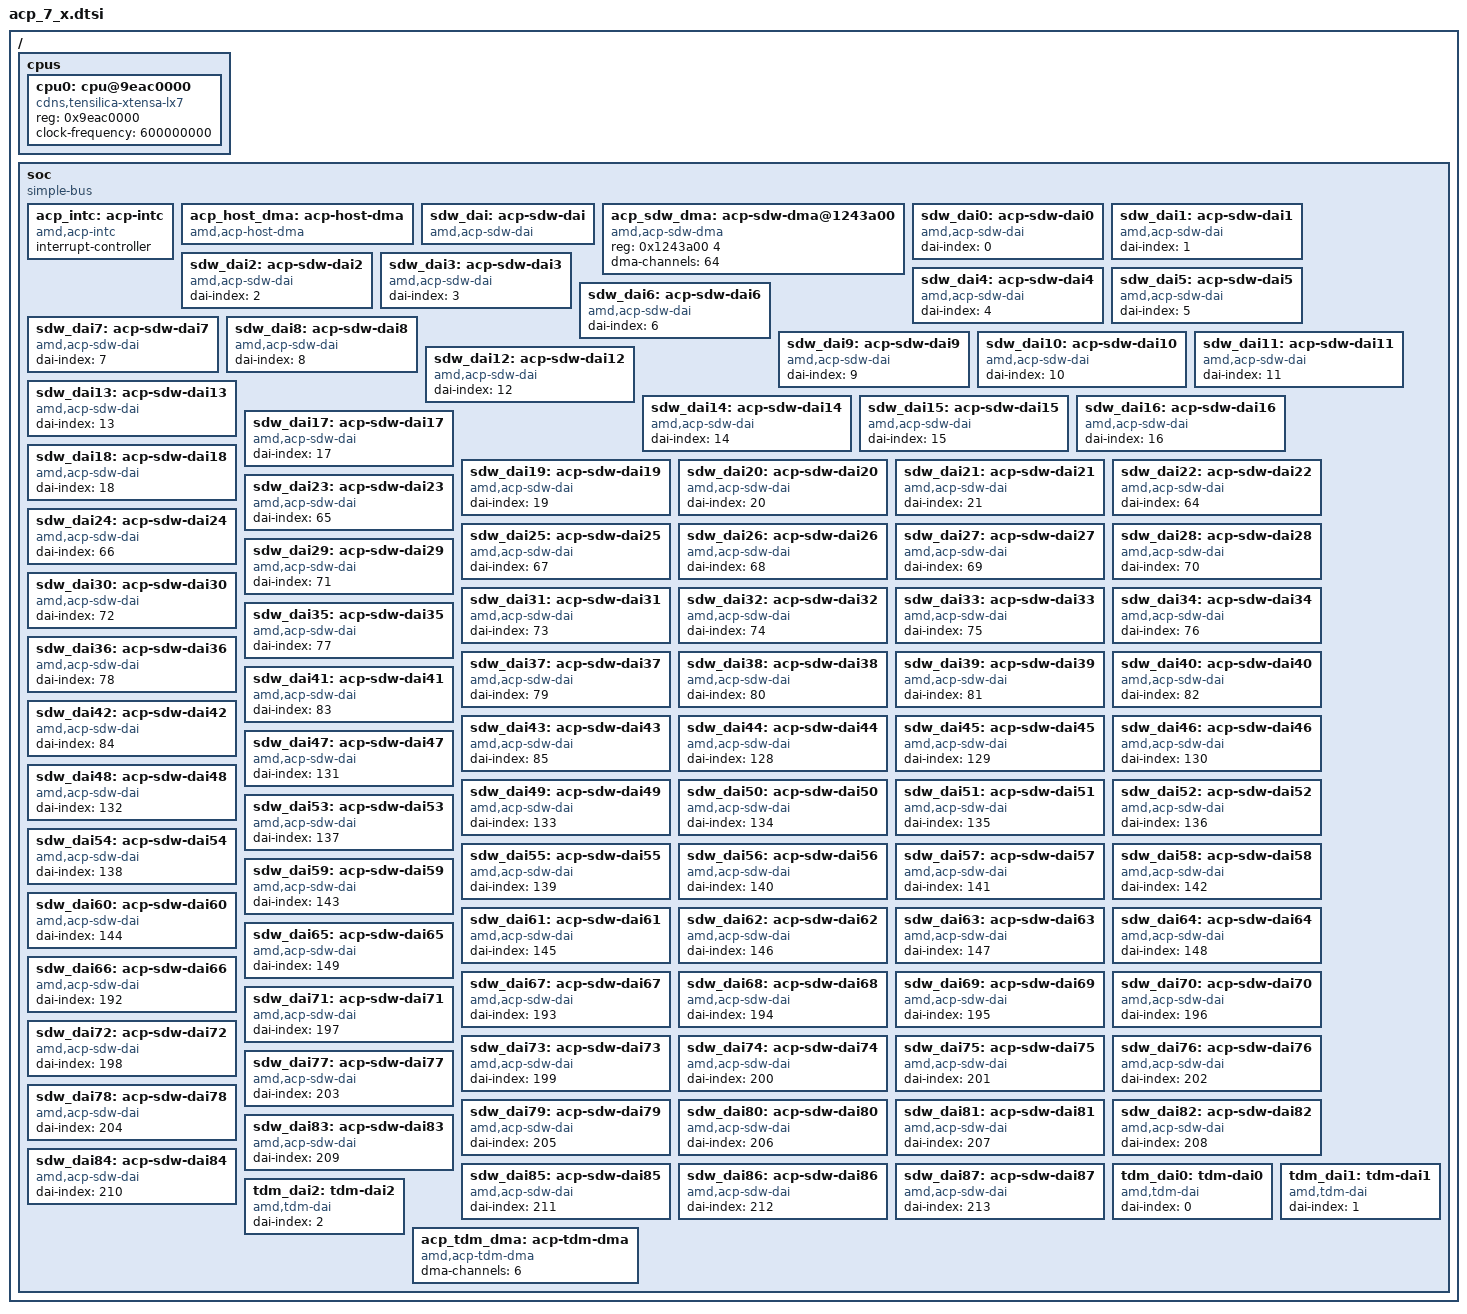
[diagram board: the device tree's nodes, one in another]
/*
 * SPDX-FileCopyrightText: Copyright (c) 2026 AMD
 *
 * SPDX-License-Identifier: Apache-2.0
 */

#include <xtensa/xtensa.dtsi>

/ {
	cpus {
		#address-cells = <1>;
		#size-cells = <0>;

		cpu0: cpu@9eac0000 {
			compatible = "cdns,tensilica-xtensa-lx7";
			reg = <0x9eac0000>;
			device_type = "cpu";
			clock-frequency = <600000000>;
		};
	};

	soc {
		compatible = "simple-bus";
		ranges;
		#address-cells = <1>;
		#size-cells = <1>;

		acp_intc: acp-intc {
			compatible = "amd,acp-intc";
			interrupt-controller;
			#interrupt-cells = <1>;
			status = "okay";
		};

		acp_host_dma: acp-host-dma {
			compatible = "amd,acp-host-dma";
			#dma-cells = <3>;
			status = "okay";
		};

		sdw_dai: acp-sdw-dai {
			compatible = "amd,acp-sdw-dai";
			status = "okay";
		};

		acp_sdw_dma: acp-sdw-dma@1243a00 {
			compatible = "amd,acp-sdw-dma";
			reg = <0x1243a00 4>;
			dma-channels = <64>;
			#dma-cells = <3>;
			status = "okay";
		};

		sdw_dai0: acp-sdw-dai0 {
			compatible = "amd,acp-sdw-dai";
			dai-index = <0>;
			status = "okay";
		};

		sdw_dai1: acp-sdw-dai1 {
			compatible = "amd,acp-sdw-dai";
			dai-index = <1>;
			status = "okay";
		};

		sdw_dai2: acp-sdw-dai2 {
			compatible = "amd,acp-sdw-dai";
			dai-index = <2>;
			status = "okay";
		};

		sdw_dai3: acp-sdw-dai3 {
			compatible = "amd,acp-sdw-dai";
			dai-index = <3>;
			status = "okay";
		};

		sdw_dai4: acp-sdw-dai4 {
			compatible = "amd,acp-sdw-dai";
			dai-index = <4>;
			status = "okay";
		};

		sdw_dai5: acp-sdw-dai5 {
			compatible = "amd,acp-sdw-dai";
			dai-index = <5>;
			status = "okay";
		};

		sdw_dai6: acp-sdw-dai6 {
			compatible = "amd,acp-sdw-dai";
			dai-index = <6>;
			status = "okay";
		};

		sdw_dai7: acp-sdw-dai7 {
			compatible = "amd,acp-sdw-dai";
			dai-index = <7>;
			status = "okay";
		};

		sdw_dai8: acp-sdw-dai8 {
			compatible = "amd,acp-sdw-dai";
			dai-index = <8>;
			status = "okay";
		};

		sdw_dai9: acp-sdw-dai9 {
			compatible = "amd,acp-sdw-dai";
			dai-index = <9>;
			status = "okay";
		};

		sdw_dai10: acp-sdw-dai10 {
			compatible = "amd,acp-sdw-dai";
			dai-index = <10>;
			status = "okay";
		};

		sdw_dai11: acp-sdw-dai11 {
			compatible = "amd,acp-sdw-dai";
			dai-index = <11>;
			status = "okay";
		};

		sdw_dai12: acp-sdw-dai12 {
			compatible = "amd,acp-sdw-dai";
			dai-index = <12>;
			status = "okay";
		};

		sdw_dai13: acp-sdw-dai13 {
			compatible = "amd,acp-sdw-dai";
			dai-index = <13>;
			status = "okay";
		};

		sdw_dai14: acp-sdw-dai14 {
			compatible = "amd,acp-sdw-dai";
			dai-index = <14>;
			status = "okay";
		};

		sdw_dai15: acp-sdw-dai15 {
			compatible = "amd,acp-sdw-dai";
			dai-index = <15>;
			status = "okay";
		};

		sdw_dai16: acp-sdw-dai16 {
			compatible = "amd,acp-sdw-dai";
			dai-index = <16>;
			status = "okay";
		};

		sdw_dai17: acp-sdw-dai17 {
			compatible = "amd,acp-sdw-dai";
			dai-index = <17>;
			status = "okay";
		};

		sdw_dai18: acp-sdw-dai18 {
			compatible = "amd,acp-sdw-dai";
			dai-index = <18>;
			status = "okay";
		};

		sdw_dai19: acp-sdw-dai19 {
			compatible = "amd,acp-sdw-dai";
			dai-index = <19>;
			status = "okay";
		};

		sdw_dai20: acp-sdw-dai20 {
			compatible = "amd,acp-sdw-dai";
			dai-index = <20>;
			status = "okay";
		};

		sdw_dai21: acp-sdw-dai21 {
			compatible = "amd,acp-sdw-dai";
			dai-index = <21>;
			status = "okay";
		};

		sdw_dai22: acp-sdw-dai22 {
			compatible = "amd,acp-sdw-dai";
			dai-index = <64>;
			status = "okay";
		};

		sdw_dai23: acp-sdw-dai23 {
			compatible = "amd,acp-sdw-dai";
			dai-index = <65>;
			status = "okay";
		};

		sdw_dai24: acp-sdw-dai24 {
			compatible = "amd,acp-sdw-dai";
			dai-index = <66>;
			status = "okay";
		};

		sdw_dai25: acp-sdw-dai25 {
			compatible = "amd,acp-sdw-dai";
			dai-index = <67>;
			status = "okay";
		};

		sdw_dai26: acp-sdw-dai26 {
			compatible = "amd,acp-sdw-dai";
			dai-index = <68>;
			status = "okay";
		};

		sdw_dai27: acp-sdw-dai27 {
			compatible = "amd,acp-sdw-dai";
			dai-index = <69>;
			status = "okay";
		};

		sdw_dai28: acp-sdw-dai28 {
			compatible = "amd,acp-sdw-dai";
			dai-index = <70>;
			status = "okay";
		};

		sdw_dai29: acp-sdw-dai29 {
			compatible = "amd,acp-sdw-dai";
			dai-index = <71>;
			status = "okay";
		};

		sdw_dai30: acp-sdw-dai30 {
			compatible = "amd,acp-sdw-dai";
			dai-index = <72>;
			status = "okay";
		};

		sdw_dai31: acp-sdw-dai31 {
			compatible = "amd,acp-sdw-dai";
			dai-index = <73>;
			status = "okay";
		};

		sdw_dai32: acp-sdw-dai32 {
			compatible = "amd,acp-sdw-dai";
			dai-index = <74>;
			status = "okay";
		};

		sdw_dai33: acp-sdw-dai33 {
			compatible = "amd,acp-sdw-dai";
			dai-index = <75>;
			status = "okay";
		};

		sdw_dai34: acp-sdw-dai34 {
			compatible = "amd,acp-sdw-dai";
			dai-index = <76>;
			status = "okay";
		};

		sdw_dai35: acp-sdw-dai35 {
			compatible = "amd,acp-sdw-dai";
			dai-index = <77>;
			status = "okay";
		};

		sdw_dai36: acp-sdw-dai36 {
			compatible = "amd,acp-sdw-dai";
			dai-index = <78>;
			status = "okay";
		};

		sdw_dai37: acp-sdw-dai37 {
			compatible = "amd,acp-sdw-dai";
			dai-index = <79>;
			status = "okay";
		};

		sdw_dai38: acp-sdw-dai38 {
			compatible = "amd,acp-sdw-dai";
			dai-index = <80>;
			status = "okay";
		};

		sdw_dai39: acp-sdw-dai39 {
			compatible = "amd,acp-sdw-dai";
			dai-index = <81>;
			status = "okay";
		};

		sdw_dai40: acp-sdw-dai40 {
			compatible = "amd,acp-sdw-dai";
			dai-index = <82>;
			status = "okay";
		};

		sdw_dai41: acp-sdw-dai41 {
			compatible = "amd,acp-sdw-dai";
			dai-index = <83>;
			status = "okay";
		};

		sdw_dai42: acp-sdw-dai42 {
			compatible = "amd,acp-sdw-dai";
			dai-index = <84>;
			status = "okay";
		};

		sdw_dai43: acp-sdw-dai43 {
			compatible = "amd,acp-sdw-dai";
			dai-index = <85>;
			status = "okay";
		};

		sdw_dai44: acp-sdw-dai44 {
			compatible = "amd,acp-sdw-dai";
			dai-index = <128>;
			status = "okay";
		};

		sdw_dai45: acp-sdw-dai45 {
			compatible = "amd,acp-sdw-dai";
			dai-index = <129>;
			status = "okay";
		};

		sdw_dai46: acp-sdw-dai46 {
			compatible = "amd,acp-sdw-dai";
			dai-index = <130>;
			status = "okay";
		};

		sdw_dai47: acp-sdw-dai47 {
			compatible = "amd,acp-sdw-dai";
			dai-index = <131>;
			status = "okay";
		};

		sdw_dai48: acp-sdw-dai48 {
			compatible = "amd,acp-sdw-dai";
			dai-index = <132>;
			status = "okay";
		};

		sdw_dai49: acp-sdw-dai49 {
			compatible = "amd,acp-sdw-dai";
			dai-index = <133>;
			status = "okay";
		};

		sdw_dai50: acp-sdw-dai50 {
			compatible = "amd,acp-sdw-dai";
			dai-index = <134>;
			status = "okay";
		};

		sdw_dai51: acp-sdw-dai51 {
			compatible = "amd,acp-sdw-dai";
			dai-index = <135>;
			status = "okay";
		};

		sdw_dai52: acp-sdw-dai52 {
			compatible = "amd,acp-sdw-dai";
			dai-index = <136>;
			status = "okay";
		};

		sdw_dai53: acp-sdw-dai53 {
			compatible = "amd,acp-sdw-dai";
			dai-index = <137>;
			status = "okay";
		};

		sdw_dai54: acp-sdw-dai54 {
			compatible = "amd,acp-sdw-dai";
			dai-index = <138>;
			status = "okay";
		};

		sdw_dai55: acp-sdw-dai55 {
			compatible = "amd,acp-sdw-dai";
			dai-index = <139>;
			status = "okay";
		};

		sdw_dai56: acp-sdw-dai56 {
			compatible = "amd,acp-sdw-dai";
			dai-index = <140>;
			status = "okay";
		};

		sdw_dai57: acp-sdw-dai57 {
			compatible = "amd,acp-sdw-dai";
			dai-index = <141>;
			status = "okay";
		};

		sdw_dai58: acp-sdw-dai58 {
			compatible = "amd,acp-sdw-dai";
			dai-index = <142>;
			status = "okay";
		};

		sdw_dai59: acp-sdw-dai59 {
			compatible = "amd,acp-sdw-dai";
			dai-index = <143>;
			status = "okay";
		};

		sdw_dai60: acp-sdw-dai60 {
			compatible = "amd,acp-sdw-dai";
			dai-index = <144>;
			status = "okay";
		};

		sdw_dai61: acp-sdw-dai61 {
			compatible = "amd,acp-sdw-dai";
			dai-index = <145>;
			status = "okay";
		};

		sdw_dai62: acp-sdw-dai62 {
			compatible = "amd,acp-sdw-dai";
			dai-index = <146>;
			status = "okay";
		};

		sdw_dai63: acp-sdw-dai63 {
			compatible = "amd,acp-sdw-dai";
			dai-index = <147>;
			status = "okay";
		};

		sdw_dai64: acp-sdw-dai64 {
			compatible = "amd,acp-sdw-dai";
			dai-index = <148>;
			status = "okay";
		};

		sdw_dai65: acp-sdw-dai65 {
			compatible = "amd,acp-sdw-dai";
			dai-index = <149>;
			status = "okay";
		};

		sdw_dai66: acp-sdw-dai66 {
			compatible = "amd,acp-sdw-dai";
			dai-index = <192>;
			status = "okay";
		};

		sdw_dai67: acp-sdw-dai67 {
			compatible = "amd,acp-sdw-dai";
			dai-index = <193>;
			status = "okay";
		};

		sdw_dai68: acp-sdw-dai68 {
			compatible = "amd,acp-sdw-dai";
			dai-index = <194>;
			status = "okay";
		};

		sdw_dai69: acp-sdw-dai69 {
			compatible = "amd,acp-sdw-dai";
			dai-index = <195>;
			status = "okay";
		};

		sdw_dai70: acp-sdw-dai70 {
			compatible = "amd,acp-sdw-dai";
			dai-index = <196>;
			status = "okay";
		};

		sdw_dai71: acp-sdw-dai71 {
			compatible = "amd,acp-sdw-dai";
			dai-index = <197>;
			status = "okay";
		};

		sdw_dai72: acp-sdw-dai72 {
			compatible = "amd,acp-sdw-dai";
			dai-index = <198>;
			status = "okay";
		};

		sdw_dai73: acp-sdw-dai73 {
			compatible = "amd,acp-sdw-dai";
			dai-index = <199>;
			status = "okay";
		};

		sdw_dai74: acp-sdw-dai74 {
			compatible = "amd,acp-sdw-dai";
			dai-index = <200>;
			status = "okay";
		};

		sdw_dai75: acp-sdw-dai75 {
			compatible = "amd,acp-sdw-dai";
			dai-index = <201>;
			status = "okay";
		};

		sdw_dai76: acp-sdw-dai76 {
			compatible = "amd,acp-sdw-dai";
			dai-index = <202>;
			status = "okay";
		};

		sdw_dai77: acp-sdw-dai77 {
			compatible = "amd,acp-sdw-dai";
			dai-index = <203>;
			status = "okay";
		};

		sdw_dai78: acp-sdw-dai78 {
			compatible = "amd,acp-sdw-dai";
			dai-index = <204>;
			status = "okay";
		};

		sdw_dai79: acp-sdw-dai79 {
			compatible = "amd,acp-sdw-dai";
			dai-index = <205>;
			status = "okay";
		};

		sdw_dai80: acp-sdw-dai80 {
			compatible = "amd,acp-sdw-dai";
			dai-index = <206>;
			status = "okay";
		};

		sdw_dai81: acp-sdw-dai81 {
			compatible = "amd,acp-sdw-dai";
			dai-index = <207>;
			status = "okay";
		};

		sdw_dai82: acp-sdw-dai82 {
			compatible = "amd,acp-sdw-dai";
			dai-index = <208>;
			status = "okay";
		};

		sdw_dai83: acp-sdw-dai83 {
			compatible = "amd,acp-sdw-dai";
			dai-index = <209>;
			status = "okay";
		};

		sdw_dai84: acp-sdw-dai84 {
			compatible = "amd,acp-sdw-dai";
			dai-index = <210>;
			status = "okay";
		};

		sdw_dai85: acp-sdw-dai85 {
			compatible = "amd,acp-sdw-dai";
			dai-index = <211>;
			status = "okay";
		};

		sdw_dai86: acp-sdw-dai86 {
			compatible = "amd,acp-sdw-dai";
			dai-index = <212>;
			status = "okay";
		};

		sdw_dai87: acp-sdw-dai87 {
			compatible = "amd,acp-sdw-dai";
			dai-index = <213>;
			status = "okay";
		};

		tdm_dai0: tdm-dai0 {
			compatible = "amd,tdm-dai";
			dai-index = <0>;
			status = "okay";
		};

		tdm_dai1: tdm-dai1 {
			compatible = "amd,tdm-dai";
			dai-index = <1>;
			status = "okay";
		};

		tdm_dai2: tdm-dai2 {
			compatible = "amd,tdm-dai";
			dai-index = <2>;
			status = "okay";
		};

		acp_tdm_dma: acp-tdm-dma {
			compatible = "amd,acp-tdm-dma";
			#dma-cells = <3>;
			dma-channels = <6>;
			status = "okay";
		};
	};
};
